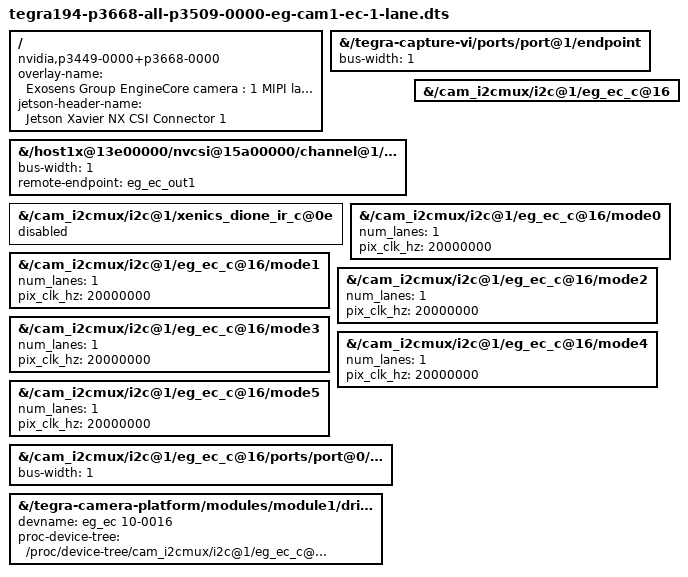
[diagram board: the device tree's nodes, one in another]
// SPDX-License-Identifier: GPL-2.0-only
/*
 * Jetson Device-tree overlay for Camera E3331 on t23x platforms
 *
 * Copyright (c) 2022 NVIDIA CORPORATION. All rights reserved.
 *
 */


/dts-v1/;
/plugin/;


/ {
	overlay-name = "Exosens Group EngineCore camera : 1 MIPI lane";
	jetson-header-name = "Jetson Xavier NX CSI Connector 1";
   compatible = "nvidia,p3449-0000+p3668-0000", "nvidia,p3449-0000+p3668-0001", "nvidia,p3509-0000+p3668-0000", "nvidia,p3509-0000+p3668-0001";

	fragment@0 {
		target-path = "/tegra-capture-vi/ports/port@1/endpoint";
		__overlay__ {
			bus-width=<1>;
		};
	};

	fragment@1 {
		target-path = "/host1x@13e00000/nvcsi@15a00000/channel@1/ports/port@0/endpoint@2";
		__overlay__ {
			bus-width=<1>;
         remote-endpoint = <&eg_ec_out1>;
		};
	};

   // Disable Dione cameras
	fragment@2 {
		target-path = "/cam_i2cmux/i2c@1/xenics_dione_ir_c@0e";
		__overlay__ {
         status = "disabled";
		};
	};

   // Enable EngineCore cameras
	fragment@3 {
		target-path = "/cam_i2cmux/i2c@1/eg_ec_c@16";
		__overlay__ {
         status = "okay";
		};
	};
	fragment@4 {   
		target-path = "/cam_i2cmux/i2c@1/eg_ec_c@16/mode0";
		__overlay__ {
         num_lanes = "1";
         pix_clk_hz = "20000000";
		};
	};
	fragment@5 {
		target-path = "/cam_i2cmux/i2c@1/eg_ec_c@16/mode1";
		__overlay__ {
         num_lanes = "1";
         pix_clk_hz = "20000000";
		};
	};
	fragment@6 {
		target-path = "/cam_i2cmux/i2c@1/eg_ec_c@16/mode2";
		__overlay__ {
         num_lanes = "1";
         pix_clk_hz = "20000000";
		};
	};
	fragment@7 {
		target-path = "/cam_i2cmux/i2c@1/eg_ec_c@16/mode3";
		__overlay__ {
         num_lanes = "1";
         pix_clk_hz = "20000000";
		};
	};
	fragment@8 {
		target-path = "/cam_i2cmux/i2c@1/eg_ec_c@16/mode4";
		__overlay__ {
         num_lanes = "1";
         pix_clk_hz = "20000000";
		};
	};
	fragment@9 {
		target-path = "/cam_i2cmux/i2c@1/eg_ec_c@16/mode5";
		__overlay__ {
         num_lanes = "1";
         pix_clk_hz = "20000000";
		};
	};
	fragment@10 {
		target-path = "/cam_i2cmux/i2c@1/eg_ec_c@16/ports/port@0/endpoint";
		__overlay__ {
			bus-width=<1>;
		};
	};

	fragment@11 {
		target-path = "/tegra-camera-platform/modules/module1/drivernode0";
		__overlay__ {
         devname = "eg_ec 10-0016";
			proc-device-tree = "/proc/device-tree/cam_i2cmux/i2c@1/eg_ec_c@16";
		};
	};
};
